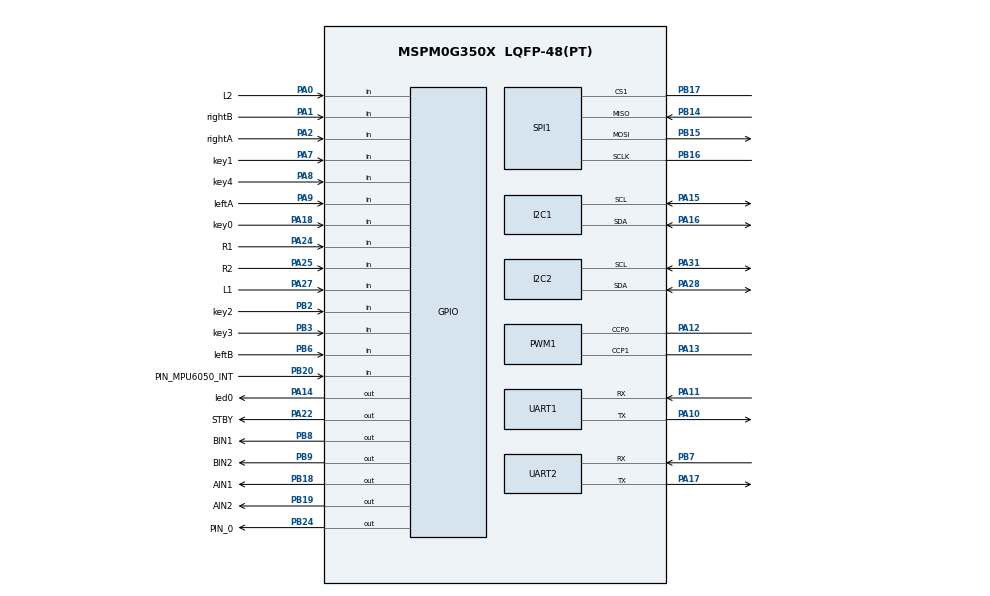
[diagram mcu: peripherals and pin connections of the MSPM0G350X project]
/**
 * @cliArgs --device "MSPM0G350X" --part "Default" --package "LQFP-48(PT)" --product "mspm0_sdk@2.11.00.07"
 * @versions {"tool":"1.26.2+4477"}
 */

/**
 * Import the modules used in this configuration.
 */
const GPIO   = scripting.addModule("/ti/driverlib/GPIO", {}, false);
const GPIO1  = GPIO.addInstance();
const GPIO2  = GPIO.addInstance();
const GPIO3  = GPIO.addInstance();
const GPIO4  = GPIO.addInstance();
const GPIO5  = GPIO.addInstance();
const GPIO6  = GPIO.addInstance();
const GPIO7  = GPIO.addInstance();
const I2C    = scripting.addModule("/ti/driverlib/I2C", {}, false);
const I2C1   = I2C.addInstance();
const I2C2   = I2C.addInstance();
const PWM    = scripting.addModule("/ti/driverlib/PWM", {}, false);
const PWM1   = PWM.addInstance();
const SPI    = scripting.addModule("/ti/driverlib/SPI", {}, false);
const SPI1   = SPI.addInstance();
const SYSCTL = scripting.addModule("/ti/driverlib/SYSCTL");
const TIMER  = scripting.addModule("/ti/driverlib/TIMER", {}, false);
const TIMER1 = TIMER.addInstance();
const UART   = scripting.addModule("/ti/driverlib/UART", {}, false);
const UART1  = UART.addInstance();
const UART2  = UART.addInstance();

/**
 * Write custom configuration values to the imported modules.
 */
const mux4       = system.clockTree["EXHFMUX"];
mux4.inputSelect = "EXHFMUX_XTAL";

const pinFunction4     = system.clockTree["HFXT"];
pinFunction4.inputFreq = 40;

GPIO1.$name                         = "LED";
GPIO1.associatedPins[0].$name       = "led0";
GPIO1.associatedPins[0].pin.$assign = "PA14";

const Board = scripting.addModule("/ti/driverlib/Board", {}, false);

GPIO2.$name                               = "KEY";
GPIO2.associatedPins.create(5);
GPIO2.associatedPins[0].direction         = "INPUT";
GPIO2.associatedPins[0].$name             = "key0";
GPIO2.associatedPins[0].hysteresisControl = "DISABLE";
GPIO2.associatedPins[0].inputFilter       = "1_CYCLE";
GPIO2.associatedPins[0].internalResistor  = "PULL_DOWN";
GPIO2.associatedPins[0].pin.$assign       = "PA18";
GPIO2.associatedPins[1].$name             = "key1";
GPIO2.associatedPins[1].direction         = "INPUT";
GPIO2.associatedPins[1].internalResistor  = "PULL_UP";
GPIO2.associatedPins[1].pin.$assign       = "PA7";
GPIO2.associatedPins[2].$name             = "key2";
GPIO2.associatedPins[2].direction         = "INPUT";
GPIO2.associatedPins[2].inputFilter       = "1_CYCLE";
GPIO2.associatedPins[2].internalResistor  = "PULL_UP";
GPIO2.associatedPins[2].pin.$assign       = "PB2";
GPIO2.associatedPins[3].$name             = "key3";
GPIO2.associatedPins[3].direction         = "INPUT";
GPIO2.associatedPins[3].inputFilter       = "3_CYCLES";
GPIO2.associatedPins[3].internalResistor  = "PULL_UP";
GPIO2.associatedPins[3].pin.$assign       = "PB3";
GPIO2.associatedPins[4].$name             = "key4";
GPIO2.associatedPins[4].direction         = "INPUT";
GPIO2.associatedPins[4].inputFilter       = "8_CYCLES";
GPIO2.associatedPins[4].internalResistor  = "PULL_UP";
GPIO2.associatedPins[4].pin.$assign       = "PA8";

GPIO3.$name                                = "Encoder";
GPIO3.associatedPins.create(4);
GPIO3.associatedPins[0].direction          = "INPUT";
GPIO3.associatedPins[0].interruptEn        = true;
GPIO3.associatedPins[0].pubChanID          = 1;
GPIO3.associatedPins[0].polarity           = "RISE_FALL";
GPIO3.associatedPins[0].$name              = "rightA";
GPIO3.associatedPins[0].pin.$assign        = "PA2";
GPIO3.associatedPins[1].direction          = "INPUT";
GPIO3.associatedPins[1].hysteresisControl  = "DISABLE";
GPIO3.associatedPins[1].hysteresisOverride = true;
GPIO3.associatedPins[1].interruptEn        = true;
GPIO3.associatedPins[1].pubChanID          = 1;
GPIO3.associatedPins[1].polarity           = "RISE_FALL";
GPIO3.associatedPins[1].$name              = "rightB";
GPIO3.associatedPins[1].pin.$assign        = "PA1";
GPIO3.associatedPins[2].direction          = "INPUT";
GPIO3.associatedPins[2].interruptEn        = true;
GPIO3.associatedPins[2].pubChanID          = 1;
GPIO3.associatedPins[2].polarity           = "RISE_FALL";
GPIO3.associatedPins[2].$name              = "leftA";
GPIO3.associatedPins[2].pin.$assign        = "PA9";
GPIO3.associatedPins[3].direction          = "INPUT";
GPIO3.associatedPins[3].internalResistor   = "PULL_DOWN";
GPIO3.associatedPins[3].interruptEn        = true;
GPIO3.associatedPins[3].polarity           = "RISE_FALL";
GPIO3.associatedPins[3].$name              = "leftB";
GPIO3.associatedPins[3].pin.$assign        = "PB6";

GPIO4.$name                              = "Patrol";
GPIO4.associatedPins.create(4);
GPIO4.associatedPins[0].$name            = "R2";
GPIO4.associatedPins[0].direction        = "INPUT";
GPIO4.associatedPins[0].internalResistor = "PULL_DOWN";
GPIO4.associatedPins[0].pin.$assign      = "PA25";
GPIO4.associatedPins[1].$name            = "R1";
GPIO4.associatedPins[1].direction        = "INPUT";
GPIO4.associatedPins[1].internalResistor = "PULL_DOWN";
GPIO4.associatedPins[1].pin.$assign      = "PA24";
GPIO4.associatedPins[2].$name            = "L1";
GPIO4.associatedPins[2].direction        = "INPUT";
GPIO4.associatedPins[2].internalResistor = "PULL_DOWN";
GPIO4.associatedPins[2].pin.$assign      = "PA27";
GPIO4.associatedPins[3].$name            = "L2";
GPIO4.associatedPins[3].direction        = "INPUT";
GPIO4.associatedPins[3].internalResistor = "PULL_DOWN";
GPIO4.associatedPins[3].pin.$assign      = "PA0";

GPIO5.$name                         = "Motor";
GPIO5.associatedPins.create(5);
GPIO5.associatedPins[0].$name       = "AIN1";
GPIO5.associatedPins[0].assignedPin = "any";
GPIO5.associatedPins[0].pin.$assign = "PB18";
GPIO5.associatedPins[1].$name       = "AIN2";
GPIO5.associatedPins[1].pin.$assign = "PB19";
GPIO5.associatedPins[2].$name       = "BIN1";
GPIO5.associatedPins[2].pin.$assign = "PB8";
GPIO5.associatedPins[3].$name       = "BIN2";
GPIO5.associatedPins[3].pin.$assign = "PB9";
GPIO5.associatedPins[4].$name       = "STBY";
GPIO5.associatedPins[4].pin.$assign = "PA22";

GPIO6.$name                         = "Beeper";
GPIO6.associatedPins[0].$name       = "PIN_0";
GPIO6.associatedPins[0].pin.$assign = "PB24";

GPIO7.$name                               = "GPIO_MPU6050";
GPIO7.associatedPins[0].$name             = "PIN_MPU6050_INT";
GPIO7.associatedPins[0].direction         = "INPUT";
GPIO7.associatedPins[0].internalResistor  = "PULL_UP";
GPIO7.associatedPins[0].interruptEn       = true;
GPIO7.associatedPins[0].interruptPriority = "3";
GPIO7.associatedPins[0].polarity          = "FALL";
GPIO7.associatedPins[0].pin.$assign       = "PB20";

I2C1.$name                             = "I2C_MPU6050";
I2C1.basicEnableController             = true;
I2C1.basicControllerStandardBusSpeed   = "Fast";
I2C1.peripheral.$assign                = "I2C1";
I2C1.peripheral.sdaPin.$assign         = "PA16";
I2C1.peripheral.sclPin.$assign         = "PA15";
I2C1.sdaPinConfig.hideOutputInversion  = scripting.forceWrite(false);
I2C1.sdaPinConfig.onlyInternalResistor = scripting.forceWrite(false);
I2C1.sdaPinConfig.passedPeripheralType = scripting.forceWrite("Digital");
I2C1.sdaPinConfig.$name                = "ti_driverlib_gpio_GPIOPinGeneric2";
I2C1.sclPinConfig.hideOutputInversion  = scripting.forceWrite(false);
I2C1.sclPinConfig.onlyInternalResistor = scripting.forceWrite(false);
I2C1.sclPinConfig.passedPeripheralType = scripting.forceWrite("Digital");
I2C1.sclPinConfig.$name                = "ti_driverlib_gpio_GPIOPinGeneric3";

I2C2.$name                             = "I2C_OLED";
I2C2.basicEnableController             = true;
I2C2.basicControllerStandardBusSpeed   = "Fast";
I2C2.peripheral.$assign                = "I2C0";
I2C2.peripheral.sdaPin.$assign         = "PA28";
I2C2.peripheral.sclPin.$assign         = "PA31";
I2C2.sdaPinConfig.hideOutputInversion  = scripting.forceWrite(false);
I2C2.sdaPinConfig.onlyInternalResistor = scripting.forceWrite(false);
I2C2.sdaPinConfig.passedPeripheralType = scripting.forceWrite("Digital");
I2C2.sdaPinConfig.$name                = "ti_driverlib_gpio_GPIOPinGeneric17";
I2C2.sclPinConfig.hideOutputInversion  = scripting.forceWrite(false);
I2C2.sclPinConfig.onlyInternalResistor = scripting.forceWrite(false);
I2C2.sclPinConfig.passedPeripheralType = scripting.forceWrite("Digital");
I2C2.sclPinConfig.$name                = "ti_driverlib_gpio_GPIOPinGeneric18";

PWM1.$name                              = "PWM_motor";
PWM1.timerStartTimer                    = true;
PWM1.pwmMode                            = "EDGE_ALIGN_UP";
PWM1.timerCount                         = 400;
PWM1.clockPrescale                      = 8;
PWM1.peripheral.$assign                 = "TIMG0";
PWM1.peripheral.ccp0Pin.$assign         = "PA12";
PWM1.peripheral.ccp1Pin.$assign         = "PA13";
PWM1.PWM_CHANNEL_0.$name                = "ti_driverlib_pwm_PWMTimerCC0";
PWM1.PWM_CHANNEL_1.$name                = "ti_driverlib_pwm_PWMTimerCC1";
PWM1.ccp0PinConfig.$name                = "ti_driverlib_gpio_GPIOPinGeneric4";
PWM1.ccp0PinConfig.direction            = scripting.forceWrite("OUTPUT");
PWM1.ccp0PinConfig.hideOutputInversion  = scripting.forceWrite(false);
PWM1.ccp0PinConfig.onlyInternalResistor = scripting.forceWrite(false);
PWM1.ccp0PinConfig.passedPeripheralType = scripting.forceWrite("Digital");
PWM1.ccp1PinConfig.$name                = "ti_driverlib_gpio_GPIOPinGeneric5";
PWM1.ccp1PinConfig.direction            = scripting.forceWrite("OUTPUT");
PWM1.ccp1PinConfig.hideOutputInversion  = scripting.forceWrite(false);
PWM1.ccp1PinConfig.onlyInternalResistor = scripting.forceWrite(false);
PWM1.ccp1PinConfig.passedPeripheralType = scripting.forceWrite("Digital");

SPI1.chipSelect                         = ["1"];
SPI1.$name                              = "SPI_Flash";
SPI1.sclkPinConfig.direction            = scripting.forceWrite("OUTPUT");
SPI1.sclkPinConfig.onlyInternalResistor = scripting.forceWrite(false);
SPI1.sclkPinConfig.passedPeripheralType = scripting.forceWrite("Digital");
SPI1.sclkPinConfig.$name                = "ti_driverlib_gpio_GPIOPinGeneric11";
SPI1.mosiPinConfig.direction            = scripting.forceWrite("OUTPUT");
SPI1.mosiPinConfig.hideOutputInversion  = scripting.forceWrite(false);
SPI1.mosiPinConfig.onlyInternalResistor = scripting.forceWrite(false);
SPI1.mosiPinConfig.passedPeripheralType = scripting.forceWrite("Digital");
SPI1.mosiPinConfig.$name                = "ti_driverlib_gpio_GPIOPinGeneric12";
SPI1.misoPinConfig.onlyInternalResistor = scripting.forceWrite(false);
SPI1.misoPinConfig.passedPeripheralType = scripting.forceWrite("Digital");
SPI1.misoPinConfig.$name                = "ti_driverlib_gpio_GPIOPinGeneric13";
SPI1.peripheral.$assign                 = "SPI1";
SPI1.peripheral.sclkPin.$assign         = "PB16";
SPI1.peripheral.mosiPin.$assign         = "PB15";
SPI1.peripheral.misoPin.$assign         = "PB14";
SPI1.peripheral.cs1Pin.$assign          = "PB17";
SPI1.cs1PinConfig.direction             = scripting.forceWrite("OUTPUT");
SPI1.cs1PinConfig.hideOutputInversion   = scripting.forceWrite(false);
SPI1.cs1PinConfig.onlyInternalResistor  = scripting.forceWrite(false);
SPI1.cs1PinConfig.passedPeripheralType  = scripting.forceWrite("Digital");
SPI1.cs1PinConfig.$name                 = "ti_driverlib_gpio_GPIOPinGeneric14";

SYSCTL.forceDefaultClkConfig = true;
SYSCTL.clockTreeEn           = true;

TIMER1.$name              = "TIMER_0";
TIMER1.interrupts         = ["ZERO"];
TIMER1.timerClkDiv        = 8;
TIMER1.timerMode          = "PERIODIC";
TIMER1.timerClkPrescale   = 100;
TIMER1.timerPeriod        = "10ms";
TIMER1.peripheral.$assign = "TIMG6";

UART1.$name                    = "UART_0";
UART1.enabledInterrupts        = ["RX"];
UART1.peripheral.$assign       = "UART0";
UART1.peripheral.rxPin.$assign = "PA11";
UART1.peripheral.txPin.$assign = "PA10";
UART1.txPinConfig.$name        = "ti_driverlib_gpio_GPIOPinGeneric0";
UART1.rxPinConfig.$name        = "ti_driverlib_gpio_GPIOPinGeneric1";

UART2.$name                    = "UART_1";
UART2.peripheral.$assign       = "UART1";
UART2.peripheral.rxPin.$assign = "PB7";
UART2.peripheral.txPin.$assign = "PA17";
UART2.txPinConfig.$name        = "ti_driverlib_gpio_GPIOPinGeneric9";
UART2.rxPinConfig.$name        = "ti_driverlib_gpio_GPIOPinGeneric10";

const ProjectConfig              = scripting.addModule("/ti/project_config/ProjectConfig", {}, false);
ProjectConfig.migrationCondition = true;

/**
 * Pinmux solution for unlocked pins/peripherals. This ensures that minor changes to the automatic solver in a future
 * version of the tool will not impact the pinmux you originally saw.  These lines can be completely deleted in order to
 * re-solve from scratch.
 */
Board.peripheral.$suggestSolution          = "DEBUGSS";
Board.peripheral.swclkPin.$suggestSolution = "PA20";
Board.peripheral.swdioPin.$suggestSolution = "PA19";
